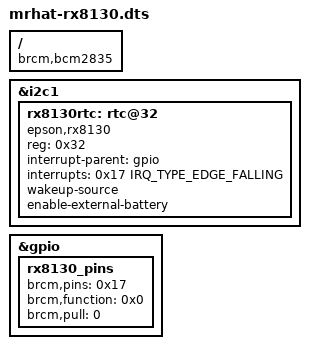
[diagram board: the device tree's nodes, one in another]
/*
* Copyright (C) 2024 Effective Range Kft.
*
* This program is free software; you can redistribute it and/or modify
* it under the terms of the GNU General Public License version 2 as
* published by the Free Software Foundation.
*/
/dts-v1/;
/plugin/;

#include <dt-bindings/gpio/gpio.h>
#include <dt-bindings/interrupt-controller/irq.h>

/ {
	compatible = "brcm,bcm2835";
	
	/*  EPSON RX8130CE RTC on I2C */
	fragment@0 {
		target = <&i2c1>;

		__overlay__ {
			status = "okay";
			#address-cells = <1>;
            #size-cells = <0>;
			/* RX8130CE */
			rx8130rtc: rtc@32 {
				compatible = "epson,rx8130";
				reg = <0x32>; /* I2C address of the RTC */
				interrupt-parent = <&gpio>;
				interrupts = <0x17 IRQ_TYPE_EDGE_FALLING>;
				wakeup-source;
				enable-external-battery;
				status = "okay";
			};
		};
	};
	fragment@1 {
		target = <&gpio>;
		__overlay__ {
			/* set up pin for RTC IRQ */
			rx8130_pins: rx8130_pins {
				brcm,pins = <0x17>;
				brcm,function = <0x0>; /* in */
				brcm,pull = <0>; /* none */
			};
		};
	};
	__overrides__ {
		/* GPIO number of interrupt pin for the RTC interrupt */
		rtc_irq_pin = <&rx8130rtc>, "interrupts:0",
		              <&rx8130_pins>, "brcm,pins:0";
		/* Enable this when RTC is powered by the main battery, charging is not enabled */
		ext_battery = <&rx8130rtc>, "enable-external-battery?";
		/* Enable this when RTC is powered by a rechargeable battery, RTC will charge the backup battery */
		ext_capacitor = <&rx8130rtc>, "enable-external-capacitor?";
		/* Enable this to support wake from alarm (with rtcwake) */
		wakeup_source = <&rx8130rtc>, "wakeup-source?";
		
	};

};
